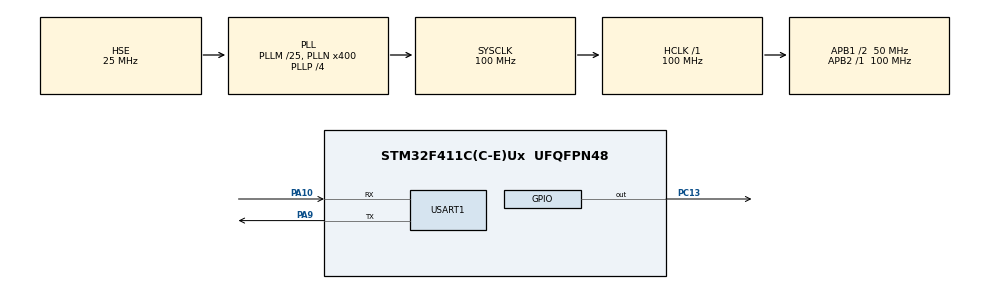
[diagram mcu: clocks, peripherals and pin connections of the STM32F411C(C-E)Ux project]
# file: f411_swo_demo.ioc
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Mcu.Family=STM32F4
Mcu.Name=STM32F411C(C-E)Ux
Mcu.Package=UFQFPN48
NVIC.PriorityGroup=NVIC_PRIORITYGROUP_4
PA10.Mode=Asynchronous
PA10.Signal=USART1_RX
PA13.Mode=Trace_Asynchronous_SW
PA13.Signal=SYS_JTMS-SWDIO
PA14.Mode=Trace_Asynchronous_SW
PA14.Signal=SYS_JTCK-SWCLK
PA9.Mode=Asynchronous
PA9.Signal=USART1_TX
PB3.Mode=Trace_Asynchronous_SW
PB3.Signal=SYS_JTDO-SWO
PC13-ANTI_TAMP.Signal=GPIO_Output
PH0\ -\ OSC_IN.Mode=HSE-External-Oscillator
PH0\ -\ OSC_IN.Signal=RCC_OSC_IN
PH1\ -\ OSC_OUT.Mode=HSE-External-Oscillator
PH1\ -\ OSC_OUT.Signal=RCC_OSC_OUT
ProjectManager.HeapSize=0x200
ProjectManager.StackSize=0x400
ProjectManager.TargetToolchain=STM32CubeIDE
RCC.48MHZClocksFreq_Value=100000000
RCC.AHBFreq_Value=100000000
RCC.APB1CLKDivider=RCC_HCLK_DIV2
RCC.APB1Freq_Value=50000000
RCC.APB1TimFreq_Value=100000000
RCC.APB2Freq_Value=100000000
RCC.APB2TimFreq_Value=100000000
RCC.CortexFreq_Value=100000000
RCC.HCLKFreq_Value=100000000
RCC.HSE_VALUE=25000000
RCC.HSI_VALUE=16000000
RCC.LSE_VALUE=32768
RCC.PLLM=25
RCC.PLLN=400
RCC.PLLP=RCC_PLLP_DIV4
RCC.PLLSourceVirtual=RCC_PLLSOURCE_HSE
RCC.SYSCLKFreq_VALUE=100000000
RCC.SYSCLKSource=RCC_SYSCLKSOURCE_PLLCLK
RCC.VCOOutputFreq_Value=400000000
USART1.VirtualMode=VM_ASYNC
board=custom

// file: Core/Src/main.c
/* USER CODE BEGIN Header */
/* Weact v1.3 STM32F411CEU6 dev board
1. 	Cubemx ioc, ensure SYS->Debug is set to 'Asychronous Trace' so that SWO, SWD and SWCLK
	pins are assigned alternate function (green)

2. 	main.c redefine  _write function or __io_putchar() so that
	printf is redirected to ITM module. Add only one of these.

int _write(int file, char* szMsg, int len) {
	for (int inx = 0; inx < len; inx++){
		ITM_SendChar(*szMsg++);
	    }
	return len;
    }
-OR-
int __io_putchar(int ch) {
	ITM_SendChar(ch);
	return ch;
    }

3. 	Add #include <stdio.h>
4. 	STM32CubeIDE  project -> debug -> configuration -> Debugger
	Select STLink GDB Server, enable Serial Wire Viewer, set the mcu clock to match with actual mcu
	clock set in project
5.	Flash the cpu, when the debugger is halted in main,
	go to Window - View - enable SWV ITM Data Console window.
	Click on settings icon,  enable channel 0
	Click on record icon (red circle) to start trace.
	Click on resume / step and you will see printf outputs on the ITM console window.
	Click on record icon to stop tracing
*/
/* USER CODE END Header */

#include "main.h"

/* USER CODE BEGIN Includes */
#include <stdio.h>
#include <stdarg.h>
#include <string.h>
/* USER CODE END Includes */

UART_HandleTypeDef huart1;

void SystemClock_Config(void);
static void MX_GPIO_Init(void);
static void MX_USART1_UART_Init(void);

/* USER CODE BEGIN 0 */

// printf retargeted to SWV ITM Data Console
int __io_putchar(int ch) {
	ITM_SendChar(ch);
	return ch;
}

void printUartSz(char *msg){
	for(int inx = 0; inx < strlen(msg); inx++)	{
		while (!(huart1.Instance->SR & UART_FLAG_TXE));
		huart1.Instance->DR = (uint16_t) msg[inx];
		}
	while (!(huart1.Instance->SR & UART_FLAG_TC));
	}

void printUart(char *format,...){
	char str[120];
	va_list args;
	va_start(args, format);
	vsprintf(str, format,args);
	printUartSz(str);
	va_end(args);
 	}

/* USER CODE END 0 */

int main(void)
{

  /* MCU Configuration--------------------------------------------------------*/

  /* Reset of all peripherals, Initializes the Flash interface and the Systick. */
  HAL_Init();

  /* USER CODE BEGIN Init */
  // Ensure Core Clock in IDE SWV
  /* USER CODE END Init */

  /* Configure the system clock */
  SystemClock_Config();

  /* Initialize all configured peripherals */
  MX_GPIO_Init();
  MX_USART1_UART_Init();
  /* USER CODE BEGIN 2 */
  int counter = 0;
  printf("hello from SWO debug\r\n");
  /* USER CODE END 2 */

  /* Infinite loop */
  while (1)
  {

    /* USER CODE BEGIN 3 */
	  HAL_GPIO_TogglePin(GPIOC, GPIO_PIN_13);
	  printUart("via uart %d\r\n", counter++);
	  printf("via swo %d\r\n", counter);
	  HAL_Delay(1000);

  }
  /* USER CODE END 3 */
}

void SystemClock_Config(void)
{
  RCC_OscInitTypeDef RCC_OscInitStruct = {0};
  RCC_ClkInitTypeDef RCC_ClkInitStruct = {0};

  /** Configure the main internal regulator output voltage
  */
  __HAL_RCC_PWR_CLK_ENABLE();
  __HAL_PWR_VOLTAGESCALING_CONFIG(PWR_REGULATOR_VOLTAGE_SCALE1);
  /** Initializes the CPU, AHB and APB busses clocks
  */
  RCC_OscInitStruct.OscillatorType = RCC_OSCILLATORTYPE_HSE;
  RCC_OscInitStruct.HSEState = RCC_HSE_ON;
  RCC_OscInitStruct.PLL.PLLState = RCC_PLL_ON;
  RCC_OscInitStruct.PLL.PLLSource = RCC_PLLSOURCE_HSE;
  RCC_OscInitStruct.PLL.PLLM = 25;
  RCC_OscInitStruct.PLL.PLLN = 400;
  RCC_OscInitStruct.PLL.PLLP = RCC_PLLP_DIV4;
  RCC_OscInitStruct.PLL.PLLQ = 4;
  if (HAL_RCC_OscConfig(&RCC_OscInitStruct) != HAL_OK)
  {
    Error_Handler();
  }
  /** Initializes the CPU, AHB and APB busses clocks
  */
  RCC_ClkInitStruct.ClockType = RCC_CLOCKTYPE_HCLK|RCC_CLOCKTYPE_SYSCLK
                              |RCC_CLOCKTYPE_PCLK1|RCC_CLOCKTYPE_PCLK2;
  RCC_ClkInitStruct.SYSCLKSource = RCC_SYSCLKSOURCE_PLLCLK;
  RCC_ClkInitStruct.AHBCLKDivider = RCC_SYSCLK_DIV1;
  RCC_ClkInitStruct.APB1CLKDivider = RCC_HCLK_DIV2;
  RCC_ClkInitStruct.APB2CLKDivider = RCC_HCLK_DIV1;

  if (HAL_RCC_ClockConfig(&RCC_ClkInitStruct, FLASH_LATENCY_3) != HAL_OK)
  {
    Error_Handler();
  }
}

static void MX_USART1_UART_Init(void)
{

  huart1.Instance = USART1;
  huart1.Init.BaudRate = 115200;
  huart1.Init.WordLength = UART_WORDLENGTH_8B;
  huart1.Init.StopBits = UART_STOPBITS_1;
  huart1.Init.Parity = UART_PARITY_NONE;
  huart1.Init.Mode = UART_MODE_TX_RX;
  huart1.Init.HwFlowCtl = UART_HWCONTROL_NONE;
  huart1.Init.OverSampling = UART_OVERSAMPLING_16;
  if (HAL_UART_Init(&huart1) != HAL_OK)
  {
    Error_Handler();
  }

}

static void MX_GPIO_Init(void)
{
  GPIO_InitTypeDef GPIO_InitStruct = {0};

  /* GPIO Ports Clock Enable */
  __HAL_RCC_GPIOC_CLK_ENABLE();
  __HAL_RCC_GPIOH_CLK_ENABLE();
  __HAL_RCC_GPIOA_CLK_ENABLE();
  __HAL_RCC_GPIOB_CLK_ENABLE();

  /*Configure GPIO pin Output Level */
  HAL_GPIO_WritePin(GPIOC, GPIO_PIN_13, GPIO_PIN_RESET);

  /*Configure GPIO pin : PC13 */
  GPIO_InitStruct.Pin = GPIO_PIN_13;
  GPIO_InitStruct.Mode = GPIO_MODE_OUTPUT_PP;
  GPIO_InitStruct.Pull = GPIO_NOPULL;
  GPIO_InitStruct.Speed = GPIO_SPEED_FREQ_LOW;
  HAL_GPIO_Init(GPIOC, &GPIO_InitStruct);

}

void Error_Handler(void)
{
  /* USER CODE BEGIN Error_Handler_Debug */
  /* User can add his own implementation to report the HAL error return state */
	int counter = 0;
	while (1) {
		HAL_GPIO_TogglePin(GPIOA, GPIO_PIN_1);
		while (counter < 0x3FFFF) {counter++;}
		counter = 0;
		}
  /* USER CODE END Error_Handler_Debug */
}

/************************ (C) COPYRIGHT STMicroelectronics *****END OF FILE****/
